# psoc6_03 register map
Vendor: Cypress Semiconductor; Series: PSoC6_03; File version: 1.0
CPU: CM4 r0p1, little endian, MPU, FPU, VTOR, 3 interrupt priority bits
Registers are 32-bit, read-write, reset 0x0 unless marked. A register's access mark holds for its fields unless they carry their own. Offsets are from the block's base; [hi:lo] are bit positions; lines under a group give offsets from that group; {n}, {i} and the like mark numbered series; 'fields as' and 'values as' point back to an identical list; <NAME> marks a mode.

## SRSS (part 1 of 2) — SRSS Core Registers
Base 0x40260000
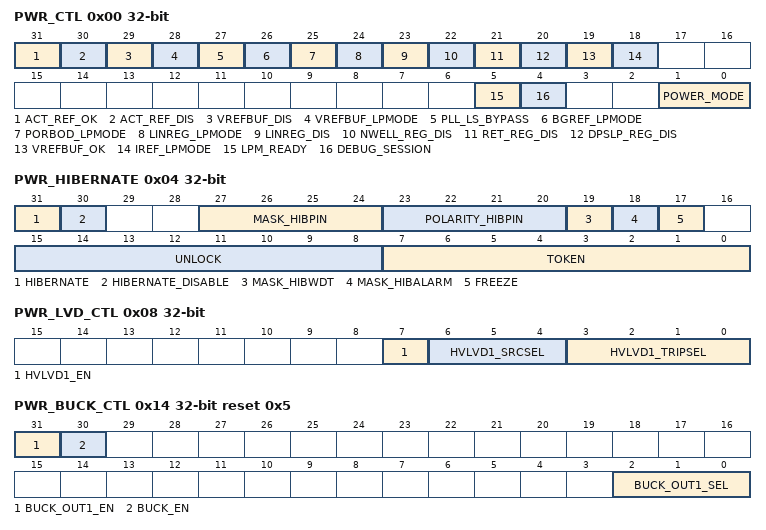
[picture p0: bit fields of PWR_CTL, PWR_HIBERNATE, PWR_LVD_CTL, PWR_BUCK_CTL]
0x00 PWR_CTL — Power Mode Control
  [31] ACT_REF_OK ro — Indicates that the normal mode of the Active Reference is ready.
  [30] ACT_REF_DIS — Disables the Active Reference. Firmware must ensure that LPM_READY==1 and BGREF_LPMODE==1 for at least 1us before disabling the Active Reference. When enabling the Active Reference, use ACT_REF_OK indicator to know when it is ready. This register is only reset by XRES/POR/BOD/HIBERNATE. 0: Active Reference is enabled 1: Active Reference is disabled
  [29] VREFBUF_DIS — Disable the 800mV voltage reference buffer. Firmware should only disable the buffer when there is no connected circuit that is using it. SRSS circuits that require it are the PLL and ECO. A particular product may have circuits outside the SRSS that use the buffer. This register is only reset by XRES/POR/BOD/HIBERNATE.
  [28] VREFBUF_LPMODE — Control the power mode of the 800mV voltage reference buffer. The value in this register is ignored and normal mode is used until LPM_READY==1. 0: Voltage Reference Buffer operates in normal mode. They work for vddd ramp rates of 100mV/us or less. This register is only reset by XRES/POR/BOD/HIBERNATE. 1: Voltage Reference Buffer operates in low power mode. Power supply rejection is reduced to save current, and they work for vddd ramp rates of 10mV/us or less.
  [27] PLL_LS_BYPASS — Bypass level shifter inside the PLL. 0: Do not bypass the level shifter. This setting is ok for all operational modes and vccd target voltage. 1: Bypass the level shifter. This may reduce jitter on the PLL output clock, but can only be used when vccd is targeted to 1.1V nominal. Otherwise, it can result in clock degradation and static current.
  [26] BGREF_LPMODE — Control the power mode of the Bandgap Voltage and Current References. This applies to voltage and current generation and is different than the reference voltage buffer. The value in this register is ignored and normal mode is used until LPM_READY==1. When lower power mode is used, the Active Reference circuit can be disabled to reduce current. Firmware is responsible to ensure ACT_REF_OK==1 before changing back to normal mode. This register is only reset by XRES/POR/BOD/HIBERNATE. 0: Active Bandgap Voltage and Current Reference operates in normal mode. They work for vddd ramp rates of 100mV/us or less. 1: Active Bandgap Voltage and Current Reference operates in low power mode. Power supply rejection is reduced to save current, and they work for vddd ramp rates of 10mV/us or less. The Active Reference may be disabled using ACT_REF_DIS=0.
  [25] PORBOD_LPMODE — Control the power mode of the POR/BOD circuits. The value in this register is ignored and normal mode is used until LPM_READY==1. This register is only reset by XRES/POR/BOD/HIBERNATE. 0: POR/BOD circuits operate in normal mode. They work for vddd ramp rates of 100mV/us or less. 1: POR/BOD circuits operate in low power mode. Response time is reduced to save current, and they work for vddd ramp rates of 10mV/us or less.
  [24] LINREG_LPMODE — Control the power mode of the Linear Regulator. The value in this register is ignored and normal mode is used until LPM_READY==1. This register is only reset by XRES/POR/BOD/HIBERNATE. 0: Linear Regulator operates in normal mode. Internal current consumption is 50uA and load current capability is 50mA to 300mA, depending on the number of regulator modules present in the product. 1: Linear Regulator operates in low power mode. Internal current consumption is 5uA and load current capability is 25mA. Firmware must ensure the current is kept within the limit.
  [23] LINREG_DIS — Disable the linear Core Regulator. This is only legal when the on-chip buck regulator supplies vccd, but there is no hardware protection for this case. This register is only reset by XRES/POR/BOD/HIBERNATE. 0: Linear regulator is on. 1: Linear regulator is off.
  [22] NWELL_REG_DIS — Disable the Nwell regulator. This is only legal when the on-chip buck regulator supplies vccd, but there is no hardware protection for this case. This register is only reset by XRES/POR/BOD/HIBERNATE. 0: Nwell Regulator is on. 1: Nwell Regulator is off.
  [21] RET_REG_DIS — Disable the Retention regulator. This is only legal when the on-chip buck regulator supplies vccd, but there is no hardware protection for this case. This register is only reset by XRES/POR/BOD/HIBERNATE. 0: Retention Regulator is on. 1: Retention Regulator is off.
  [20] DPSLP_REG_DIS — Disable the DeepSleep regulator. This is only legal when the on-chip buck regulator supplies vccd, but there is no hardware protection for this case. This register is only reset by XRES/POR/BOD/HIBERNATE. 0: DeepSleep Regulator is on. 1: DeepSleep Regulator is off.
  [19] VREFBUF_OK ro — Indicates that the voltage reference buffer is ready. Due to synchronization delays, it may take two IMO clock cycles for hardware to clear this bit after asserting VREFBUF_DIS=1.
  [18] IREF_LPMODE — Control the power mode of the reference current generator. The value in this register is ignored and normal mode is used until LPM_READY==1. This register is only reset by XRES/POR/BOD/HIBERNATE. 0: Current reference generator operates in normal mode. It works for vddd ramp rates of 100mV/us or less. 1: Current reference generator operates in low power mode. Response time is reduced to save current, and it works for vddd ramp rates of 10mV/us or less.
  [5] LPM_READY ro — Indicates whether certain low power functions are ready. The low current circuits take longer to startup after XRES/POR/BOD/HIBERNATE wakeup than the normal mode circuits. HIBERNATE mode may be entered regardless of this bit. This register is only reset by XRES/POR/BOD/HIBERNATE. 0: If a low power circuit operation is requested, it will stay in its normal operating mode until it is ready. If DEEPSLEEP is requested by all processors WFI/WFE, the device will instead enter SLEEP. When low power circuits are ready, device will automatically enter the originally requested mode. 1: Normal operation. DEEPSLEEP and low power circuits operate as requested in other registers.
  [4] DEBUG_SESSION ro — Indicates whether a debug session is active (CDBGPWRUPREQ signal is 1)
    0=NO_SESSION (No debug session active); 1=SESSION_ACTIVE (Debug session is active. Power modes behave differently to keep the debug session active.)
  [1:0] POWER_MODE ro — Current power mode of the device. Note that this field cannot be read in all power modes on actual silicon.
    0=RESET (System is resetting.); 1=ACTIVE (At least one CPU is running.); 2=SLEEP (No CPUs are running. Peripherals may be running.); 3=DEEPSLEEP (Main high-frequency clock is off; low speed clocks are available. Communication interface clocks may be present.)
0x04 PWR_HIBERNATE — HIBERNATE Mode Register
  [31] HIBERNATE — Firmware sets this bit to enter HIBERNATE mode. The system will enter HIBERNATE mode immediately after writing to this bit and will wakeup only in response to XRES or WAKEUP event. Both UNLOCK and FREEZE must have been set correctly in a previous write operations. Otherwise, it will not enter HIBERNATE. External supplies must have been stable for 250us before entering HIBERNATE mode.
  [30] HIBERNATE_DISABLE — Hibernate disable bit. 0: Normal operation, HIBERNATE works as described 1: Further writes to this register are ignored Note: This bit is a write-once bit until the next reset. Avoid changing any other bits in this register while disabling HIBERNATE mode. Also, it is recommended to clear the UNLOCK code, if it was previously written..
  [27:24] MASK_HIBPIN — When set, HIBERNATE will wakeup if the corresponding pin input matches the POLARITY_HIBPIN setting. Each bit corresponds to one of the wakeup pins.
  [23:20] POLARITY_HIBPIN — Each bit sets the active polarity of the corresponding wakeup pin. 0: Pin input of 0 will wakeup the part from HIBERNATE 1: Pin input of 1 will wakeup the part from HIBERNATE
  [19] MASK_HIBWDT — When set, HIBERNATE will wakeup if WDT matches
  [18] MASK_HIBALARM — When set, HIBERNATE will wakeup for a RTC interrupt
  [17] FREEZE — Firmware sets this bit to freeze the configuration, mode and state of all GPIOs and SIOs in the system. When entering HIBERNATE mode, the first write instructs DEEPSLEEP peripherals that they cannot ignore the upcoming freeze command. This occurs even in the illegal condition where UNLOCK is not set. If UNLOCK and HIBERNATE are properly set, the IOs actually freeze on the second write.
  [15:8] UNLOCK — This byte must be set to 0x3A for FREEZE or HIBERNATE fields to operate. Any other value in this register will cause FREEZE/HIBERNATE to have no effect, except as noted in the FREEZE description.
  [7:0] TOKEN — Contains a 8-bit token that is retained through a HIBERNATE/WAKEUP sequence that can be used by firmware to differentiate WAKEUP from a general RESET event. Note that waking up from HIBERNATE using XRES will reset this register.
0x08 PWR_LVD_CTL — Low Voltage Detector (LVD) Configuration Register
  [7] HVLVD1_EN — Enable HVLVD1 voltage monitor. When the LVD is enabled, it takes 20us for it to settle. There is no hardware stabilization counter, and it may falsely trigger during settling. It is recommended that firmware keep the interrupt masked for at least 8us, write a 1'b1 to the corresponding SRSS_INTR field to any falsely pended interrupt, and then optionally unmask the interrupt. After enabling, it is further recommended to read the related PWR_LVD_STATUS field, since the interrupt only triggers on edges. This bit is cleared (LVD is disabled) when entering DEEPSLEEP to prevent false interrupts during wakeup.
  [6:4] HVLVD1_SRCSEL — Source selection for HVLVD1
    0=VDDD (Select VDDD); 1=AMUXBUSA (Select AMUXBUSA (VDDD branch)); 2=RSVD (N/A); 3=VDDIO (N/A); 4=AMUXBUSB (Select AMUXBUSB (VDDD branch))
  [3:0] HVLVD1_TRIPSEL — Threshold selection for HVLVD1. Disable the LVD (HVLVD1_EN=0) before changing the threshold. 0: rise=1.225V (nom), fall=1.2V (nom) 1: rise=1.425V (nom), fall=1.4V (nom) 2: rise=1.625V (nom), fall=1.6V (nom) 3: rise=1.825V (nom), fall=1.8V (nom) 4: rise=2.025V (nom), fall=2V (nom) 5: rise=2.125V (nom), fall=2.1V (nom) 6: rise=2.225V (nom), fall=2.2V (nom) 7: rise=2.325V (nom), fall=2.3V (nom) 8: rise=2.425V (nom), fall=2.4V (nom) 9: rise=2.525V (nom), fall=2.5V (nom) 10: rise=2.625V (nom), fall=2.6V (nom) 11: rise=2.725V (nom), fall=2.7V (nom) 12: rise=2.825V (nom), fall=2.8V (nom) 13: rise=2.925V (nom), fall=2.9V (nom) 14: rise=3.025V (nom), fall=3.0V (nom) 15: rise=3.125V (nom), fall=3.1V (nom)
0x14 PWR_BUCK_CTL reset 0x5 — Buck Control Register
  [31] BUCK_OUT1_EN — Enable for vccbuck1 output. The value in this register is ignored unless PWR_BUCK_CTL.BUCK_EN==1. This register is only reset by XRES/POR/BOD/HIBERNATE. The regulator takes up to 600us to charge the external capacitor. If there is additional load current while charging, this will increase the startup time. The TRM specifies the required sequence when transitioning vccd from the LDO to SIMO Buck output #1.
  [30] BUCK_EN — Master enable for buck converter. This register is only reset by XRES/POR/BOD/HIBERNATE.
  [2:0] BUCK_OUT1_SEL — Voltage output selection for vccbuck1 output. This register is only reset by XRES/POR/BOD/HIBERNATE. When increasing the voltage, it can take up to 200us for the output voltage to settle. When decreasing the voltage, the settling time depends on the load current. 0: 0.85V 1: 0.875V 2: 0.90V 3: 0.95V 4: 1.05V 5: 1.10V 6: 1.15V 7: 1.20V
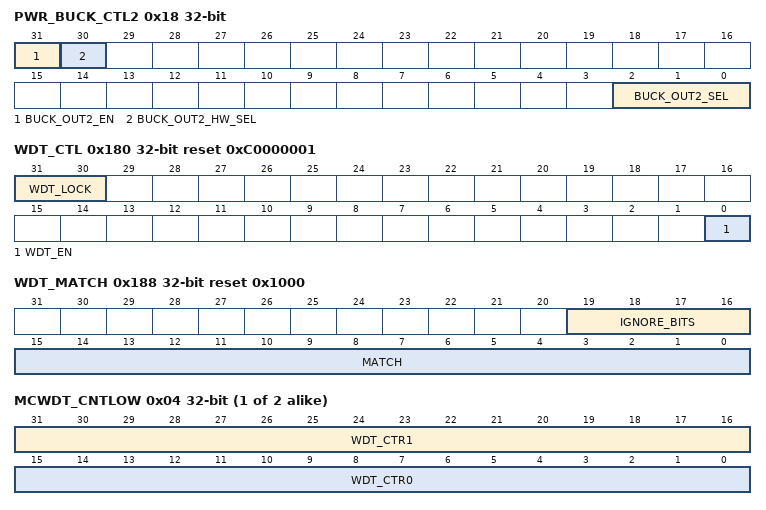
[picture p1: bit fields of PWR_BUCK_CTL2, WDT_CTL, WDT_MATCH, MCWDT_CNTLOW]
0x18 PWR_BUCK_CTL2 — Buck Control Register 2
  [31] BUCK_OUT2_EN — Enable for vccbuck2 output. The value in this register is ignored unless PWR_BUCK_CTL.BUCK_EN==1. The regulator takes up to 600us to charge the external capacitor. If there is additional load current while charging, this will increase the startup time.
  [30] BUCK_OUT2_HW_SEL — Hardware control for vccbuck2 output. When this bit is set, the value in BUCK_OUT2_EN is ignored and a hardware signal is used instead. If the product has supporting hardware, it can directly control the enable signal for vccbuck2. The same charging time in BUCK_OUT2_EN applies.
  [2:0] BUCK_OUT2_SEL — Voltage output selection for vccbuck2 output. When increasing the voltage, it can take up to 200us for the output voltage to settle. When decreasing the voltage, the settling time depends on the load current. 0: 1.15V 1: 1.20V 2: 1.25V 3: 1.30V 4: 1.35V 5: 1.40V 6: 1.45V 7: 1.50V
0x1C PWR_LVD_STATUS ro — Low Voltage Detector (LVD) Status Register
  [0] HVLVD1_OK — HVLVD1 output. 0: below voltage threshold 1: above voltage threshold
{0x80+4i} PWR_HIB_DATA[{i}] (i=0..15) — HIBERNATE Data Register
  [31:0] HIB_DATA — Additional data that is retained through a HIBERNATE/WAKEUP sequence that can be used by firmware for any application-specific purpose. Note that waking up from HIBERNATE using XRES will reset this register.
0x180 WDT_CTL reset 0xC0000001 — Watchdog Counter Control Register
  [31:30] WDT_LOCK — Prohibits writing to WDT_*, CLK_ILO_CONFIG, CLK_SELECT.LFCLK_SEL, and CLK_TRIM_ILO_CTL registers when not equal 0. Requires at least two different writes to unlock. A change in WDT_LOCK takes effect beginning with the next write cycle. Note that this field is 2 bits to force multiple writes only. It represents only a single write protect signal protecting all those registers at the same time. WDT will lock on any reset. This field is not retained during DEEPSLEEP or HIBERNATE mode, so the WDT will be locked after wakeup from these modes.
    0=NO_CHG (No effect); 1=CLR0 (Clears bit 0); 2=CLR1 (Clears bit 1); 3=SET01 (Sets both bits 0 and 1)
  [0] WDT_EN — Enable this watchdog timer. This field is retained during DEEPSLEEP and HIBERNATE modes.
0x184 WDT_CNT — Watchdog Counter Count Register
  [15:0] COUNTER — Current value of WDT Counter. The write feature of this register is for engineering use (DfV), have no synchronization, and can only be applied when the WDT is fully off. When writing, the value is updated immediately in the WDT counter, but it will read back as the old value until this register resynchronizes just after the negedge of ILO. Writes will be ignored if they occur when the WDT is enabled.
0x188 WDT_MATCH reset 0x1000 — Watchdog Counter Match Register
  [19:16] IGNORE_BITS — The number of MSB bits of the watchdog timer that are NOT checked against MATCH. This value provides control over the time-to-reset of the watchdog (which happens after 3 successive matches). Up to 12 MSB can be ignored. Settings >12 behave like a setting of 12.
  [15:0] MATCH — Match value for Watchdog counter. Every time WDT_COUNTER reaches MATCH an interrupt is generated. Two unserviced interrupts will lead to a system reset (i.e. at the third match).
{0x200+0x40*i} MCWDT_STRUCT[{i}] (i=0..1) group — Multi-Counter Watchdog Timer
  0x04 MCWDT_CNTLOW — Multi-Counter Watchdog Sub-counters 0/1
    [31:16] WDT_CTR1 — Current value of sub-counter 1 for this MCWDT. Software writes are ignored when the sub-counter is enabled
    [15:0] WDT_CTR0 — Current value of sub-counter 0 for this MCWDT. Software writes are ignored when the sub-counter is enabled.
  0x08 MCWDT_CNTHIGH — Multi-Counter Watchdog Sub-counter 2
    [31:0] WDT_CTR2 — Current value of sub-counter 2 for this MCWDT. Software writes are ignored when the sub-counter is enabled
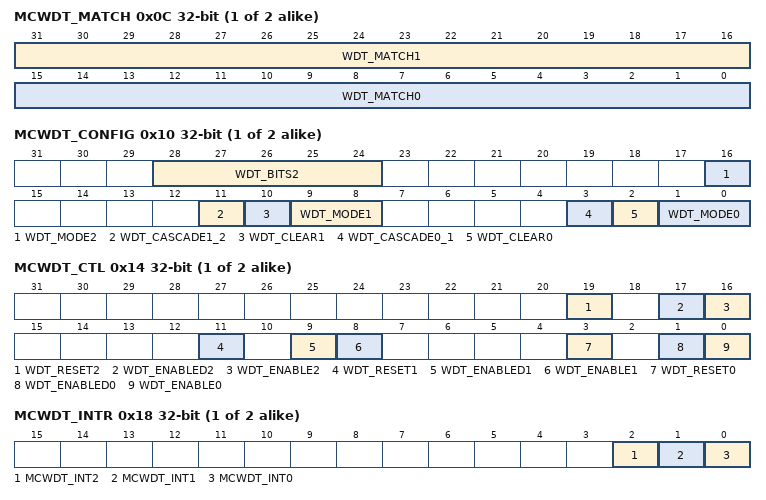
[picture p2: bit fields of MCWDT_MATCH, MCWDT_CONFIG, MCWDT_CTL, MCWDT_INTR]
  0x0C MCWDT_MATCH — Multi-Counter Watchdog Counter Match Register
    [31:16] WDT_MATCH1 — Match value for sub-counter 1 of this MCWDT
    [15:0] WDT_MATCH0 — Match value for sub-counter 0 of this MCWDT
  0x10 MCWDT_CONFIG — Multi-Counter Watchdog Counter Configuration
    [28:24] WDT_BITS2 — Bit to observe for WDT_INT2: 0: Assert after bit0 of WDT_CTR2 toggles (one int every tick) ... 31: Assert after bit31 of WDT_CTR2 toggles (one int every 2^31 ticks)
    [16] WDT_MODE2 — Watchdog Counter 2 Mode.
      0=NOTHING (Free running counter with no interrupt requests); 1=INT (Free running counter with interrupt request that occurs one LFCLK cycle after the specified bit in CTR2 toggles (see WDT_BITS2).)
    [11] WDT_CASCADE1_2 — Cascade Watchdog Counters 1,2. Counter 2 increments the cycle after WDT_CTR1=WDT_MATCH1. It is allowed to cascade all three WDT counters. 0: Independent counters 1: Cascaded counters. When cascading all three counters, WDT_CLEAR1 must be 1.
    [10] WDT_CLEAR1 — Clear Watchdog Counter when WDT_CTR1==WDT_MATCH1. In other words WDT_CTR1 divides LFCLK by (WDT_MATCH1+1). 0: Free running counter 1: Clear on match. In this mode, the minimum legal setting of WDT_MATCH1 is 1.
    [9:8] WDT_MODE1 — Watchdog Counter Action on Match. Action is taken on the next increment after the values match (WDT_CTR1=WDT_MATCH1).
      0=NOTHING (Do nothing); 1=INT (Assert WDT_INTx); 2=RESET (Assert WDT Reset); 3=INT_THEN_RESET (Assert WDT_INTx, assert WDT Reset after 3rd unhandled interrupt)
    [3] WDT_CASCADE0_1 — Cascade Watchdog Counters 0,1. Counter 1 increments the cycle after WDT_CTR0=WDT_MATCH0. 0: Independent counters 1: Cascaded counters
    [2] WDT_CLEAR0 — Clear Watchdog Counter when WDT_CTR0=WDT_MATCH0. In other words WDT_CTR0 divides LFCLK by (WDT_MATCH0+1). 0: Free running counter 1: Clear on match. In this mode, the minimum legal setting of WDT_MATCH0 is 1.
    [1:0] WDT_MODE0 — Watchdog Counter Action on Match. Action is taken on the next increment after the values match (WDT_CTR0=WDT_MATCH0).
      values as WDT_MODE1
  0x14 MCWDT_CTL — Multi-Counter Watchdog Counter Control
    [19] WDT_RESET2 — Resets counter 2 back to 0000. Hardware will reset this bit after counter was reset. This will take up to one LFCLK cycle to take effect.
    [17] WDT_ENABLED2 ro — Indicates actual state of counter. May lag WDT_ENABLE2 by up to two LFCLK cycles.
    [16] WDT_ENABLE2 — Enable subcounter 2. May take up to 2 LFCLK cycles to take effect. 0: Counter is disabled (not clocked) 1: Counter is enabled (counting up)
    [11] WDT_RESET1 — Resets counter 1 back to 0000. Hardware will reset this bit after counter was reset. This will take up to one LFCLK cycle to take effect.
    [9] WDT_ENABLED1 ro — Indicates actual state of counter. May lag WDT_ENABLE1 by up to two LFCLK cycles.
    [8] WDT_ENABLE1 — Enable subcounter 1. May take up to 2 LFCLK cycles to take effect. 0: Counter is disabled (not clocked) 1: Counter is enabled (counting up)
    [3] WDT_RESET0 — Resets counter 0 back to 0000. Hardware will reset this bit after counter was reset. This will take up to one LFCLK cycle to take effect.
    [1] WDT_ENABLED0 ro — Indicates actual state of counter. May lag WDT_ENABLE0 by up to two LFCLK cycles.
    [0] WDT_ENABLE0 — Enable subcounter 0. May take up to 2 LFCLK cycles to take effect. 0: Counter is disabled (not clocked) 1: Counter is enabled (counting up)
  0x18 MCWDT_INTR — Multi-Counter Watchdog Counter Interrupt Register
    [2] MCWDT_INT2 — MCWDT Interrupt Request for sub-counter 2. This bit is set by hardware as configured by this registers. This bit must be cleared by firmware. Clearing this bit also prevents Reset from happening when WDT_MODE2=3.
    [1] MCWDT_INT1 — MCWDT Interrupt Request for sub-counter 1. This bit is set by hardware as configured by this registers. This bit must be cleared by firmware. Clearing this bit also prevents Reset from happening when WDT_MODE1=3.
    [0] MCWDT_INT0 — MCWDT Interrupt Request for sub-counter 0. This bit is set by hardware as configured by this registers. This bit must be cleared by firmware. Clearing this bit also prevents Reset from happening when WDT_MODE0=3.
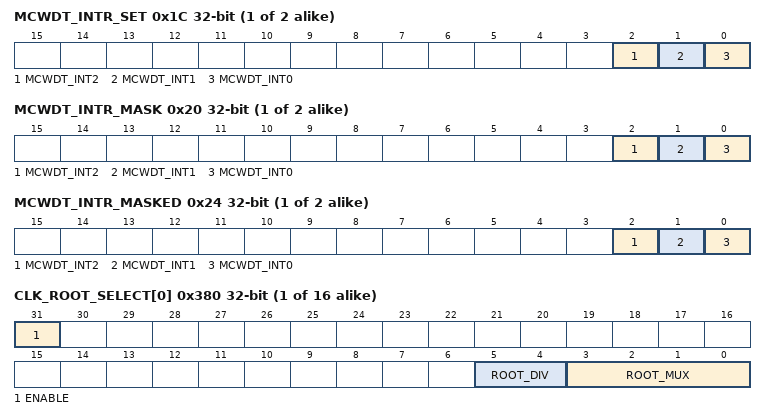
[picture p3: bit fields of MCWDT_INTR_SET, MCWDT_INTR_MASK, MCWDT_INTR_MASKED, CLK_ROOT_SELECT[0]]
  0x1C MCWDT_INTR_SET — Multi-Counter Watchdog Counter Interrupt Set Register
    [2] MCWDT_INT2 — Set interrupt for MCWDT_INT2
    [1] MCWDT_INT1 — Set interrupt for MCWDT_INT1
    [0] MCWDT_INT0 — Set interrupt for MCWDT_INT0
  0x20 MCWDT_INTR_MASK — Multi-Counter Watchdog Counter Interrupt Mask Register
    [2] MCWDT_INT2 — Mask for sub-counter 2
    [1] MCWDT_INT1 — Mask for sub-counter 1
    [0] MCWDT_INT0 — Mask for sub-counter 0
  0x24 MCWDT_INTR_MASKED ro — Multi-Counter Watchdog Counter Interrupt Masked Register
    [2] MCWDT_INT2 — Logical and of corresponding request and mask bits.
    [1] MCWDT_INT1 — Logical and of corresponding request and mask bits.
    [0] MCWDT_INT0 — Logical and of corresponding request and mask bits.
  0x28 MCWDT_LOCK — Multi-Counter Watchdog Counter Lock Register
    [31:30] MCWDT_LOCK — Prohibits writing control and configuration registers related to this MCWDT when not equal 0 (as specified in the other register descriptions). Requires at least two different writes to unlock. Note that this field is 2 bits to force multiple writes only. Each MCWDT has a separate local lock. LFCLK settings are locked by the global WDT_LOCK register, and this register has no effect on that.
      values as WDT_CTL.WDT_LOCK
{0x300+4i} CLK_DSI_SELECT[{i}] (i=0..15) — Clock DSI Select Register
  [4:0] DSI_MUX — Selects a DSI source or low frequency clock for use in a clock path. The output of this mux can be selected for clock PATH<i> using CLK_SELECT_PATH register. Using the output of this mux as HFCLK source will result in undefined behavior. It can be used to clocks to DSI or to the reference inputs of FLL/PLL, subject to the frequency limits of those circuits. This mux is not glitch free, so do not change the selection while it is an actively selected clock.
    {v}=DSI_OUT{v} (DSI{v} - dsi_out[{v}]) (v=0..15); 16=ILO (ILO - Internal Low-speed Oscillator); 17=WCO (WCO - Watch-Crystal Oscillator); 18=ALTLF (ALTLF - Alternate Low-Frequency Clock); 19=PILO (PILO - Precision Internal Low-speed Oscillator)
{0x340+4i} CLK_PATH_SELECT[{i}] (i=0..15) — Clock Path Select Register
  [2:0] PATH_MUX — Selects a source for clock PATH<i>. Note that not all products support all clock sources. Selecting a clock source that is not supported will result in undefined behavior.
    0=IMO (IMO - Internal R/C Oscillator); 1=EXTCLK (EXTCLK - External Clock Pin); 2=ECO (ECO - External-Crystal Oscillator); 3=ALTHF (ALTHF - Alternate High-Frequency clock input (product-specific clock)); 4=DSI_MUX (DSI_MUX - Output of DSI mux for this path. Using a DSI source directly as root of HFCLK will result in undefined behavior.)
{0x380+4i} CLK_ROOT_SELECT[{i}] (i=0..15) — Clock Root Select Register
  [31] ENABLE — Enable for this clock root. All clock roots default to disabled (ENABLE==0) except HFCLK0, which cannot be disabled.
  [5:4] ROOT_DIV — Selects predivider value for this clock root and DSI input.
    0=NO_DIV (Transparent mode, feed through selected clock source w/o dividing.); 1=DIV_BY_2 (Divide selected clock source by 2); 2=DIV_BY_4 (Divide selected clock source by 4); 3=DIV_BY_8 (Divide selected clock source by 8)
  [3:0] ROOT_MUX — Selects a clock path as the root of HFCLK<k> and for SRSS DSI input <k>. Use CLK_SELECT_PATH[i] to configure the desired path. Some paths may have FLL or PLL available (product-specific), and the control and bypass mux selections of these are in other registers. Configure the FLL using CLK_FLL_CONFIG register. Configure a PLL using the related CLK_PLL_CONFIG[k] register. Note that not all products support all clock sources. Selecting a clock source that is not supported will result in undefined behavior.
    0=PATH0 (Select PATH0 (can be configured for FLL)); {v}=PATH{v} (Select PATH{v} (can be configured for PLL{v-1}, if available in the product)) (v=1..15)
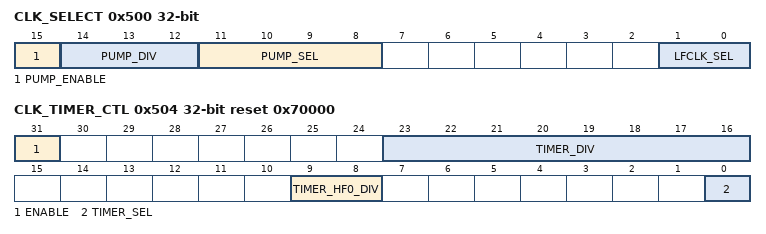
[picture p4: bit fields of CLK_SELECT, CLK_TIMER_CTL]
0x500 CLK_SELECT — Clock selection register
  [15] PUMP_ENABLE — Enable the pump clock. PUMP_ENABLE and the PUMP_SEL mux are not glitch-free to minimize side-effects, avoid changing the PUMP_SEL and PUMP_DIV while changing PUMP_ENABLE. To change the settings, do the following: 1) If the pump clock is enabled, write PUMP_ENABLE=0 without changing PUMP_SEL and PUMP_DIV. 2) Change PUMP_SEL and PUMP_DIV to desired settings with PUMP_ENABLE=0. 3) Write PUMP_ENABLE=1 without changing PUMP_SEL and PUMP_DIV.
  [14:12] PUMP_DIV — Division ratio for PUMPCLK. Uses selected PUMP_SEL clock as the source.
    0=NO_DIV (Transparent mode, feed through selected clock source w/o dividing.); 1=DIV_BY_2 (Divide selected clock source by 2); 2=DIV_BY_4 (Divide selected clock source by 4); 3=DIV_BY_8 (Divide selected clock source by 8); 4=DIV_BY_16 (Divide selected clock source by 16)
  [11:8] PUMP_SEL — Selects clock PATH<k>, where k=PUMP_SEL. The output of this mux goes to the PUMP_DIV to make PUMPCLK Each product has a specific number of available clock paths. Selecting a path that is not implemented on a product will result in undefined behavior. Note that this is not a glitch free mux.
  [1:0] LFCLK_SEL — Select source for LFCLK. Note that not all products support all clock sources. Selecting a clock source that is not supported will result in undefined behavior. Writes to this field are ignored unless the WDT is unlocked using WDT_LOCK register.
    0=ILO (ILO - Internal Low-speed Oscillator); 1=WCO (WCO - Watch-Crystal Oscillator. Requires Backup domain to be present and properly configured (including external watch crystal, if used).); 2=ALTLF (ALTLF - Alternate Low-Frequency Clock. Capability is product-specific); 3=PILO (PILO - Precision ILO. If present, it works in DEEPSLEEP and higher modes. Does not work in HIBERNATE mode.)
0x504 CLK_TIMER_CTL reset 0x70000 — Timer Clock Control Register
  [31] ENABLE — Enable for TIMERCLK. 0: TIMERCLK is off 1: TIMERCLK is enabled
  [23:16] TIMER_DIV — Divide selected timer clock source by (1+TIMER_DIV). The output of this divider is TIMERCLK Allows for integer divisions in the range [1, 256]. Do not change this setting while the timer is enabled.
  [9:8] TIMER_HF0_DIV — Predivider used when HF0_DIV is selected in TIMER_SEL. If HFCLK0 frequency is less than 100MHz and has approximately 50 percent duty cycle, then no division is required (NO_DIV). Otherwise, select a divide ratio of 2, 4, or 8 before selected HF0_DIV as the timer clock.
    0=NO_DIV (Transparent mode, feed through selected clock source w/o dividing or correcting duty cycle.); 1=DIV_BY_2 (Divide HFCLK0 by 2.); 2=DIV_BY_4 (Divide HFCLK0 by 4.); 3=DIV_BY_8 (Divide HFCLK0 by 8.)
  [0] TIMER_SEL — Select source for TIMERCLK. The output of this mux can be further divided using TIMER_DIV.
    0=IMO (IMO - Internal Main Oscillator); 1=HF0_DIV (Select the output of the predivider configured by TIMER_HF0_DIV.)
